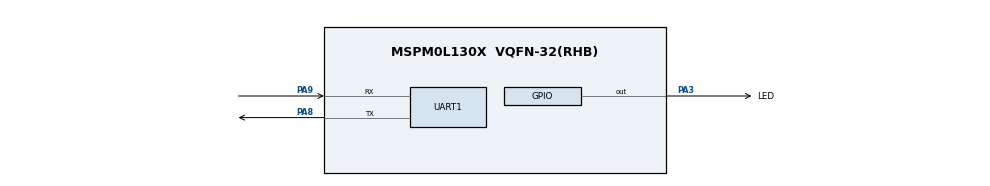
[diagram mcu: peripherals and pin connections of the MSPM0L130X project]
/**
 * @cliArgs --device "MSPM0L130X" --part "Default" --package "VQFN-32(RHB)" --product "mspm0_sdk@2.11.00.07"
 * @versions {"tool":"1.26.2+4477"}
 */

/**
 * Import the modules used in this configuration.
 */
const Board  = scripting.addModule("/ti/driverlib/Board");
const GPIO   = scripting.addModule("/ti/driverlib/GPIO", {}, false);
const GPIO1  = GPIO.addInstance();
const SYSCTL = scripting.addModule("/ti/driverlib/SYSCTL");
const UART   = scripting.addModule("/ti/driverlib/UART", {}, false);
const UART1  = UART.addInstance();

/**
 * Write custom configuration values to the imported modules.
 */
Board.configureUnused = true;

GPIO1.port                          = "PORTA";
GPIO1.$name                         = "GPIO_LED";
GPIO1.associatedPins[0].$name       = "LED";
GPIO1.associatedPins[0].pin.$assign = "PA3";

SYSCTL.clockTreeEn = true;

UART1.$name                    = "UART_0";
UART1.targetBaudRate           = 115200;
UART1.rxFifoThreshold          = "DL_UART_RX_FIFO_LEVEL_ONE_ENTRY";
UART1.enableDMARX              = false;
UART1.enableDMATX              = false;
UART1.enableInternalLoopback   = false;
UART1.enabledInterrupts        = ["RX"];
UART1.enableFIFO               = false;
UART1.peripheral.$assign       = "UART0";
UART1.peripheral.rxPin.$assign = "PA9";
UART1.peripheral.txPin.$assign = "PA8";
UART1.txPinConfig.$name        = "ti_driverlib_gpio_GPIOPinGeneric0";
UART1.rxPinConfig.$name        = "ti_driverlib_gpio_GPIOPinGeneric1";

/**
 * Pinmux solution for unlocked pins/peripherals. This ensures that minor changes to the automatic solver in a future
 * version of the tool will not impact the pinmux you originally saw.  These lines can be completely deleted in order to
 * re-solve from scratch.
 */
Board.peripheral.$suggestSolution          = "DEBUGSS";
Board.peripheral.swclkPin.$suggestSolution = "PA20";
Board.peripheral.swdioPin.$suggestSolution = "PA19";
